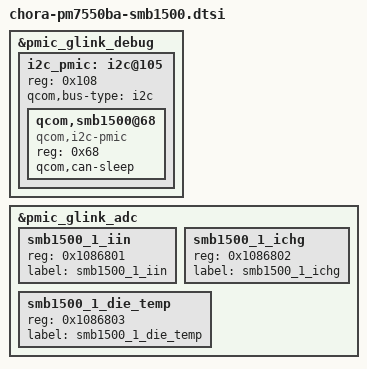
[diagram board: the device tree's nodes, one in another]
// SPDX-License-Identifier: BSD-3-Clause
/*
 * Copyright (c) Qualcomm Technologies, Inc. and/or its subsidiaries.
 */

#include "chora-pm7550ba.dtsi"

&pmic_glink_debug {
	i2c_pmic: i2c@105 {
		reg = <0x108>;  /* I2C instance 8 in ADSP for SE0 QUP 1 */
		#address-cells = <1>;
		#size-cells = <0>;
		qcom,bus-type = "i2c";

		qcom,smb1500@68 {
			compatible = "qcom,i2c-pmic";
			reg = <0x68>;
			qcom,can-sleep;
		};
	};
};

&pmic_glink_adc {
	status = "ok";

	smb1500_1_iin {
		reg = <0x1086801>;
		label = "smb1500_1_iin";
	};

	smb1500_1_ichg {
		reg = <0x1086802>;
		label = "smb1500_1_ichg";
	};

	smb1500_1_die_temp {
		reg = <0x1086803>;
		label = "smb1500_1_die_temp";
	};
};
